# ATmega16U2 register map
Vendor: Atmel; File version: 1.0
CPU: other r0p0, little endian, no MPU, no FPU, 4 interrupt priority bits
Registers are 8-bit, read-write, reset 0x0 unless marked. A register's access mark holds for its fields unless they carry their own. Offsets are from the block's base; [hi:lo] are bit positions; {n}, {i} and the like mark numbered series.

## EEPROM
Base 0x0000003F
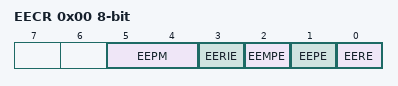
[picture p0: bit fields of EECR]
0x00 EECR — EEPROM Control Register
  [5:4] EEPM — EEPROM Programming Mode Bits
    0=Erase and Write in one operation; 1=Erase Only; 2=Write Only
  [3] EERIE — EEPROM Ready Interrupt Enable
  [2] EEMPE — EEPROM Master Write Enable
  [1] EEPE — EEPROM Write Enable
  [0] EERE — EEPROM Read Enable
0x01 EEDR — EEPROM Data Register
  [7:0] EEDR — EEPROM Data bits
0x02 EEAR 16-bit (reset mask 0xFF) — EEPROM Address Register Low Bytes
  [11:0] EEAR — EEPROM Address bits

## EXINT — External Interrupts
Base 0x0000003B
0x00 PCIFR — Pin Change Interrupt Flag Register
  [1:0] PCIF — Pin Change Interrupt Flags
0x01 EIFR — External Interrupt Flag Register
  [7:0] INTF — External Interrupt Flags
0x02 EIMSK — External Interrupt Mask Register
  [7:0] INT — External Interrupt Request 7 Enable
0x2D PCICR — Pin Change Interrupt Control Register
  [1:0] PCIE — Pin Change Interrupt Enables
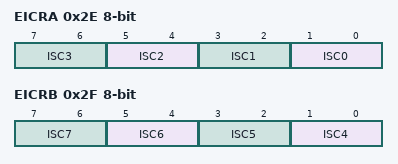
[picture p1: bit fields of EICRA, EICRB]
0x2E EICRA — External Interrupt Control Register A
  [2n+1:2n] ISC{n} (n=0..3) — External Interrupt Sense Control Bit
0x2F EICRB — External Interrupt Control Register B
  [2n-7:2n-8] ISC{n} (n=4..7) — External Interrupt 7-4 Sense Control Bit
0x30 PCMSK0 — Pin Change Mask Register 0
  [7:0] PCINT — Pin Change Enable Masks
0x31 PCMSK1 — Pin Change Mask Register 1
  [4:0] PCINT

## LOCKBIT — Lockbits
Base 0x00000000
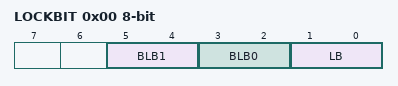
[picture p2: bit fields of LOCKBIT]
0x00 LOCKBIT
  [5:4] BLB1 — Boot Loader Protection Mode
    0=LPM_SPM_DISABLE (LPM and SPM prohibited in Boot Section); 1=LPM_DISABLE (LPM prohibited in Boot Section); 2=SPM_DISABLE (SPM prohibited in Boot Section); 3=NO_LOCK (No lock on SPM and LPM in Boot Section)
  [3:2] BLB0 — Boot Loader Protection Mode
    0=LPM_SPM_DISABLE (LPM and SPM prohibited in Application Section); 1=LPM_DISABLE (LPM prohibited in Application Section); 2=SPM_DISABLE (SPM prohibited in Application Section); 3=NO_LOCK (No lock on SPM and LPM in Application Section)
  [1:0] LB — Memory Lock
    0=PROG_VER_DISABLED (Further programming and verification disabled); 2=PROG_DISABLED (Further programming disabled); 3=NO_LOCK (No memory lock features enabled)

## PLL — Phase Locked Loop
Base 0x00000049
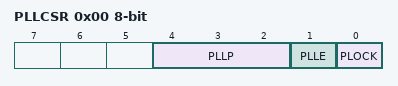
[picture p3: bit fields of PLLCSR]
0x00 PLLCSR — PLL Status and Control register
  [4:2] PLLP — PLL prescaler Bits
    3=Clock/4; 5=Clock/8
  [1] PLLE — PLL Enable Bit
  [0] PLOCK — PLL Lock Status Bit

## PORTB — I/O Port
Base 0x00000023
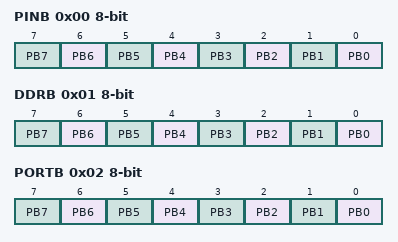
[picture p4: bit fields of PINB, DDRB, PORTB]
0x00 PINB — Port B Input Pins
  [n] PB{n} (n=0..7) — Pin B{n}
0x01 DDRB — Port B Data Direction Register
  [n] PB{n} (n=0..7) — Pin B{n}
0x02 PORTB — Port B Data Register
  [n] PB{n} (n=0..7) — Pin B{n}

## PORTC — I/O Port
Base 0x00000026
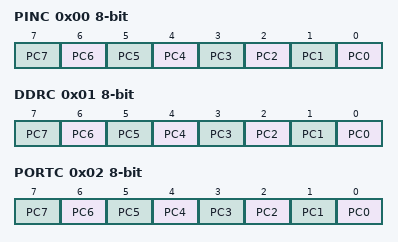
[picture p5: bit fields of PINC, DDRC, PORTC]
0x00 PINC — Port C Input Pins
  [n] PC{n} (n=0..7) — Pin C{n}
0x01 DDRC — Port C Data Direction Register
  [n] PC{n} (n=0..7) — Pin C{n}
0x02 PORTC — Port C Data Register
  [n] PC{n} (n=0..7) — Pin C{n}

## PORTD — I/O Port
Base 0x00000029
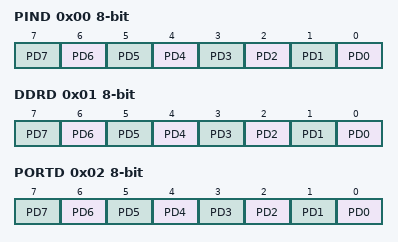
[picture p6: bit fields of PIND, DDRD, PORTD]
0x00 PIND — Port D Input Pins
  [n] PD{n} (n=0..7) — Pin D{n}
0x01 DDRD — Port D Data Direction Register
  [n] PD{n} (n=0..7) — Pin D{n}
0x02 PORTD — Port D Data Register
  [n] PD{n} (n=0..7) — Pin D{n}

## SPI — Serial Peripheral Interface
Base 0x0000004C
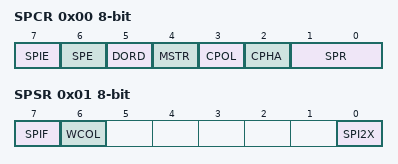
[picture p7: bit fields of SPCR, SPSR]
0x00 SPCR — SPI Control Register
  [7] SPIE — SPI Interrupt Enable
  [6] SPE — SPI Enable
  [5] DORD — Data Order
  [4] MSTR — Master/Slave Select
  [3] CPOL — Clock polarity
  [2] CPHA — Clock Phase
  [1:0] SPR — SPI Clock Rate Selects
    0=fosc/4; 1=fosc/16; 2=fosc/64; 3=fosc/128
0x01 SPSR — SPI Status Register
  [7] SPIF — SPI Interrupt Flag
  [6] WCOL — Write Collision Flag
  [0] SPI2X — Double SPI Speed Bit
0x02 SPDR — SPI Data Register
  [7:0] SPDR — SPI Data bits
